AUTOSAR XML (schema 00052)
package /apd/AdaptiveApplicationSwComponentTypes
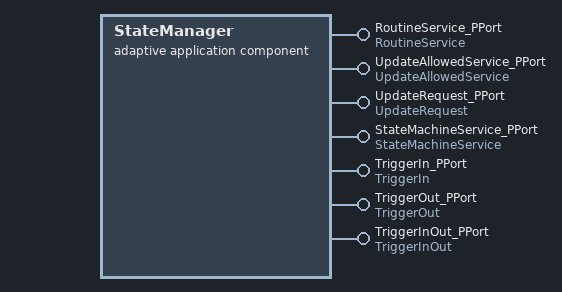
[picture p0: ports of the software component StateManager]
  adaptive application sw component type StateManager
    7 x provide port:
      RoutineService_PPort: provided-interface=RoutineService
      UpdateAllowedService_PPort: provided-interface=UpdateAllowedService
      UpdateRequest_PPort: provided-interface=UpdateRequest
      StateMachineService_PPort: provided-interface=StateMachineService
      TriggerIn_PPort: provided-interface=TriggerIn
      TriggerOut_PPort: provided-interface=TriggerOut
      TriggerInOut_PPort: provided-interface=TriggerInOut
package /apd/Executables
  executable StateManager: category=APPLICATION_LEVEL, minimum-timer-granularity=1000
    root sw component prototype StateManager: application-type=StateManager
